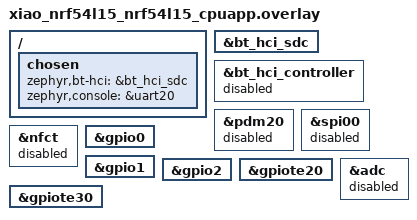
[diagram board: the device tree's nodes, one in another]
/ {
	chosen {
		zephyr,bt-hci = &bt_hci_sdc;
		zephyr,console = &uart20;
	};
};

/* Use Nordic SoftDevice Controller for Channel Sounding */
&bt_hci_sdc {
	status = "okay";
};

/* Disable Zephyr BLE controller */
&bt_hci_controller {
	status = "disabled";
};

/* Disable PDM to free up UART20 */
&pdm20 {
	status = "disabled";
};



/*
&cpuapp_sram {
	reg = <0x20000000 DT_SIZE_K(256)>;
	ranges = <0x0 0x20000000  0x40000>;
};
 */

&spi00 {
	status = "disabled";
};

&nfct {
	status = "disabled";
};

&gpio0 {
	status = "okay";
};

&gpio1 {
	status = "okay";
};

&gpio2 {
	status = "okay";
};

&gpiote20 {
	status = "okay";
};

&gpiote30 {
	status = "okay";
};

&adc {
	status = "disabled";
};
